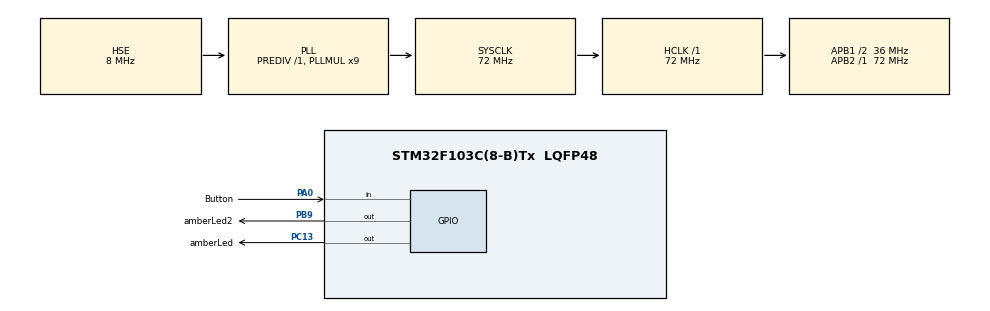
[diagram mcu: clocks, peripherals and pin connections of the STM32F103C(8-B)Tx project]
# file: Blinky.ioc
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Mcu.Family=STM32F1
Mcu.Name=STM32F103C(8-B)Tx
Mcu.Package=LQFP48
Mcu.UserConstants=TIMER1_COUNTER,100000
NVIC.PriorityGroup=NVIC_PRIORITYGROUP_4
NVIC.TIM1_UP_IRQn=true\:0\:0\:false\:false\:true
PA0-WKUP.GPIO_Label=Button
PA0-WKUP.GPIO_PuPd=GPIO_PULLUP
PA0-WKUP.Signal=GPIO_Input
PA13.Mode=Serial_Wire
PA13.Signal=SYS_JTMS-SWDIO
PA14.Mode=Serial_Wire
PA14.Signal=SYS_JTCK-SWCLK
PB9.GPIO_Label=amberLed2
PB9.PinState=GPIO_PIN_SET
PB9.Signal=GPIO_Output
PC13-TAMPER-RTC.GPIO_Label=amberLed
PC13-TAMPER-RTC.PinState=GPIO_PIN_SET
PC13-TAMPER-RTC.Signal=GPIO_Output
PD0-OSC_IN.Mode=HSE-External-Oscillator
PD0-OSC_IN.Signal=RCC_OSC_IN
PD1-OSC_OUT.Mode=HSE-External-Oscillator
PD1-OSC_OUT.Signal=RCC_OSC_OUT
ProjectManager.HeapSize=0x200
ProjectManager.StackSize=0x400
ProjectManager.TargetToolchain=SW4STM32
RCC.AHBFreq_Value=72000000
RCC.APB1CLKDivider=RCC_HCLK_DIV2
RCC.APB1Freq_Value=36000000
RCC.APB1TimFreq_Value=72000000
RCC.APB2Freq_Value=72000000
RCC.APB2TimFreq_Value=72000000
RCC.HCLKFreq_Value=72000000
RCC.PLLMUL=RCC_PLL_MUL9
RCC.PLLSourceVirtual=RCC_PLLSOURCE_HSE
RCC.SYSCLKFreq_VALUE=72000000
RCC.SYSCLKSource=RCC_SYSCLKSOURCE_PLLCLK
RCC.USBFreq_Value=72000000
TIM1.CounterMode=TIM_COUNTERMODE_UP
TIM1.Period=TIMER1_COUNTER
TIM1.TIM_MasterOutputTrigger=TIM_TRGO_UPDATE
VP_TIM1_VS_ClockSourceINT.Mode=Internal
board=Blinky

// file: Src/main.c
/**
  ******************************************************************************
  * File Name          : main.c
  * Description        : Main program body
  ******************************************************************************
  ** This notice applies to any and all portions of this file
  * that are not between comment pairs USER CODE BEGIN and
  * USER CODE END. Other portions of this file, whether
  * inserted by the user or by software development tools
  * are owned by their respective copyright owners.
  *
  * COPYRIGHT(c) 2017 STMicroelectronics
  *
  * Redistribution and use in source and binary forms, with or without modification,
  * are permitted provided that the following conditions are met:
  *   1. Redistributions of source code must retain the above copyright notice,
  *      this list of conditions and the following disclaimer.
  *   2. Redistributions in binary form must reproduce the above copyright notice,
  *      this list of conditions and the following disclaimer in the documentation
  *      and/or other materials provided with the distribution.
  *   3. Neither the name of STMicroelectronics nor the names of its contributors
  *      may be used to endorse or promote products derived from this software
  *      without specific prior written permission.
  *
  * THIS SOFTWARE IS PROVIDED BY THE COPYRIGHT HOLDERS AND CONTRIBUTORS "AS IS"
  * AND ANY EXPRESS OR IMPLIED WARRANTIES, INCLUDING, BUT NOT LIMITED TO, THE
  * IMPLIED WARRANTIES OF MERCHANTABILITY AND FITNESS FOR A PARTICULAR PURPOSE ARE
  * DISCLAIMED. IN NO EVENT SHALL THE COPYRIGHT HOLDER OR CONTRIBUTORS BE LIABLE
  * FOR ANY DIRECT, INDIRECT, INCIDENTAL, SPECIAL, EXEMPLARY, OR CONSEQUENTIAL
  * DAMAGES (INCLUDING, BUT NOT LIMITED TO, PROCUREMENT OF SUBSTITUTE GOODS OR
  * SERVICES; LOSS OF USE, DATA, OR PROFITS; OR BUSINESS INTERRUPTION) HOWEVER
  * CAUSED AND ON ANY THEORY OF LIABILITY, WHETHER IN CONTRACT, STRICT LIABILITY,
  * OR TORT (INCLUDING NEGLIGENCE OR OTHERWISE) ARISING IN ANY WAY OUT OF THE USE
  * OF THIS SOFTWARE, EVEN IF ADVISED OF THE POSSIBILITY OF SUCH DAMAGE.
  *
  ******************************************************************************
  */
#include "main.h"
#include "stm32f1xx_hal.h"

/* USER CODE BEGIN Includes */
#include "Task.h"
#include "LinkedList.h"
/* USER CODE END Includes */

TIM_HandleTypeDef htim1;

/* USER CODE BEGIN PV */
/* Private variables ---------------------------------------------------------*/
int mySignal = 8;
//TCB *currTcb;
linkedList *list;
/* USER CODE END PV */

void SystemClock_Config(void);
static void MX_GPIO_Init(void);
static void MX_TIM1_Init(void);

/* USER CODE BEGIN PFP */
/* Private function prototypes -----------------------------------------------*/
/*int add2Integers(int, int);
int add4Integers(int, int, int, int);
int add5Integers(int, int, int, int, int);
int add6Integers(int, int, int, int, int, int);
int assemblyMain(void);*/
int sub2Integers(int v1, int v2);
int sub5Integers(int v1, int v2, int v3, int v4, int v5);
int sub6Integers(int v1, int v2, int v3, int v4, int v5, int v6);
void task1(void);
void task2(void);
/* USER CODE END PFP */

/* USER CODE BEGIN 0 */
enum blink{on, off};
enum led{led1, led2};
uint32_t tickLed1;
uint32_t tickLed2;
/* USER CODE END 0 */

int main(void)
{

  /* USER CODE BEGIN 1 */
  /*enum blink led1State=on;
  enum blink led2State=on;
  enum led LED=led1;*/
  tickLed1 = HAL_GetTick();
  tickLed2 = HAL_GetTick();
  //TCB *tcb;
  listElement *element;
  volatile int j;
  /* USER CODE END 1 */

  /* MCU Configuration----------------------------------------------------------*/

  /* Reset of all peripherals, Initializes the Flash interface and the Systick. */
  HAL_Init();

  /* Configure the system clock */
  SystemClock_Config();

  /* Initialize all configured peripherals */
  MX_GPIO_Init();
  MX_TIM1_Init();

  /* USER CODE BEGIN 2 */
  /*currTcb = initKernel("MainThread");
  tcb = createThread("Thread1", task1, 256);
  currTcb->next = tcb;
  tcb = createThread("Thread2", task2, 512);
  currTcb->next->next = tcb;
  currTcb->next->next->next = currTcb;*/

  list = initLinkedList();
  element = initElement("MainThread", NULL, 0);
  addElementToBack(list, element);
  element = initElement("Thread1", task1, 256);
  addElementToBack(list, element);
  element = initElement("Thread2", task2, 512);
  addElementToBack(list, element);

  //assemblyMain();
  __HAL_TIM_ENABLE(&htim1);
  HAL_TIM_Base_Start_IT(&htim1);
  /*volatile int val = add2Integers(23, 56);
  volatile int val2 = add4Integers(21, 5, 10, 26);
  volatile int val3 = add5Integers(1, 2, 3, 4, 5);
  volatile int val4 = add6Integers(2, 3, 4, 5, 8, 6);
  if(SCB->CCR & SCB_CCR_STKALIGN){
	  val = val2;
  }*/

  /* USER CODE END 2 */

  /* Infinite loop */
  while (1)
  {

  /* USER CODE BEGIN 3 */

	  j=1;
	  /*uint32_t tick = 0;
	  HAL_GPIO_TogglePin(amberLed2_GPIO_Port, amberLed2_Pin);

	  tick = osKernelSysTick();
	  while(osKernelSysTick() - tick < 500);*/
	  /*switch(LED){
	  case led1:
		  if((HAL_GetTick()-tickLed1) >= 75){
			  HAL_GPIO_TogglePin(amberLed2_GPIO_Port, amberLed2_Pin);
			  tickLed1=HAL_GetTick();
		  }
		  LED=led2;
		  break;
	  case led2:
		  if((HAL_GetTick()-tickLed2) >= 500){
			  HAL_GPIO_TogglePin(amberLed_GPIO_Port, amberLed_Pin);
			  tickLed2=HAL_GetTick();
		  }
		  LED=led1;
		  break;
	  default:
		  LED=led1;
	  }*/

	  /*HAL_GPIO_TogglePin(amberLed_GPIO_Port, amberLed_Pin);
	  HAL_Delay(500);
	  HAL_GPIO_TogglePin(amberLed2_GPIO_Port, amberLed2_Pin);
	  HAL_Delay(75);*/
  }
  /* USER CODE END 3 */

}

/** System Clock Configuration
*/
void SystemClock_Config(void)
{

  RCC_OscInitTypeDef RCC_OscInitStruct;
  RCC_ClkInitTypeDef RCC_ClkInitStruct;

    /**Initializes the CPU, AHB and APB busses clocks
    */
  RCC_OscInitStruct.OscillatorType = RCC_OSCILLATORTYPE_HSE;
  RCC_OscInitStruct.HSEState = RCC_HSE_ON;
  RCC_OscInitStruct.HSEPredivValue = RCC_HSE_PREDIV_DIV1;
  RCC_OscInitStruct.HSIState = RCC_HSI_ON;
  RCC_OscInitStruct.PLL.PLLState = RCC_PLL_ON;
  RCC_OscInitStruct.PLL.PLLSource = RCC_PLLSOURCE_HSE;
  RCC_OscInitStruct.PLL.PLLMUL = RCC_PLL_MUL9;
  if (HAL_RCC_OscConfig(&RCC_OscInitStruct) != HAL_OK)
  {
    _Error_Handler(__FILE__, __LINE__);
  }

    /**Initializes the CPU, AHB and APB busses clocks
    */
  RCC_ClkInitStruct.ClockType = RCC_CLOCKTYPE_HCLK|RCC_CLOCKTYPE_SYSCLK
                              |RCC_CLOCKTYPE_PCLK1|RCC_CLOCKTYPE_PCLK2;
  RCC_ClkInitStruct.SYSCLKSource = RCC_SYSCLKSOURCE_PLLCLK;
  RCC_ClkInitStruct.AHBCLKDivider = RCC_SYSCLK_DIV1;
  RCC_ClkInitStruct.APB1CLKDivider = RCC_HCLK_DIV2;
  RCC_ClkInitStruct.APB2CLKDivider = RCC_HCLK_DIV1;

  if (HAL_RCC_ClockConfig(&RCC_ClkInitStruct, FLASH_LATENCY_2) != HAL_OK)
  {
    _Error_Handler(__FILE__, __LINE__);
  }

    /**Configure the Systick interrupt time
    */
  HAL_SYSTICK_Config(HAL_RCC_GetHCLKFreq()/1000);

    /**Configure the Systick
    */
  HAL_SYSTICK_CLKSourceConfig(SYSTICK_CLKSOURCE_HCLK);

  /* SysTick_IRQn interrupt configuration */
  HAL_NVIC_SetPriority(SysTick_IRQn, 0, 0);
}

/* TIM1 init function */
static void MX_TIM1_Init(void)
{

  TIM_ClockConfigTypeDef sClockSourceConfig;
  TIM_MasterConfigTypeDef sMasterConfig;

  htim1.Instance = TIM1;
  htim1.Init.Prescaler = 0;
  htim1.Init.CounterMode = TIM_COUNTERMODE_UP;
  htim1.Init.Period = TIMER1_COUNTER;
  htim1.Init.ClockDivision = TIM_CLOCKDIVISION_DIV1;
  htim1.Init.RepetitionCounter = 0;
  if (HAL_TIM_Base_Init(&htim1) != HAL_OK)
  {
    _Error_Handler(__FILE__, __LINE__);
  }

  sClockSourceConfig.ClockSource = TIM_CLOCKSOURCE_INTERNAL;
  if (HAL_TIM_ConfigClockSource(&htim1, &sClockSourceConfig) != HAL_OK)
  {
    _Error_Handler(__FILE__, __LINE__);
  }

  sMasterConfig.MasterOutputTrigger = TIM_TRGO_UPDATE;
  sMasterConfig.MasterSlaveMode = TIM_MASTERSLAVEMODE_DISABLE;
  if (HAL_TIMEx_MasterConfigSynchronization(&htim1, &sMasterConfig) != HAL_OK)
  {
    _Error_Handler(__FILE__, __LINE__);
  }

}

/** Configure pins as
        * Analog
        * Input
        * Output
        * EVENT_OUT
        * EXTI
*/
static void MX_GPIO_Init(void)
{

  GPIO_InitTypeDef GPIO_InitStruct;

  /* GPIO Ports Clock Enable */
  __HAL_RCC_GPIOC_CLK_ENABLE();
  __HAL_RCC_GPIOD_CLK_ENABLE();
  __HAL_RCC_GPIOA_CLK_ENABLE();
  __HAL_RCC_GPIOB_CLK_ENABLE();

  /*Configure GPIO pin Output Level */
  HAL_GPIO_WritePin(amberLed_GPIO_Port, amberLed_Pin, GPIO_PIN_SET);

  /*Configure GPIO pin Output Level */
  HAL_GPIO_WritePin(amberLed2_GPIO_Port, amberLed2_Pin, GPIO_PIN_SET);

  /*Configure GPIO pin : amberLed_Pin */
  GPIO_InitStruct.Pin = amberLed_Pin;
  GPIO_InitStruct.Mode = GPIO_MODE_OUTPUT_PP;
  GPIO_InitStruct.Speed = GPIO_SPEED_FREQ_LOW;
  HAL_GPIO_Init(amberLed_GPIO_Port, &GPIO_InitStruct);

  /*Configure GPIO pin : Button_Pin */
  GPIO_InitStruct.Pin = Button_Pin;
  GPIO_InitStruct.Mode = GPIO_MODE_INPUT;
  GPIO_InitStruct.Pull = GPIO_PULLUP;
  HAL_GPIO_Init(Button_GPIO_Port, &GPIO_InitStruct);

  /*Configure GPIO pin : amberLed2_Pin */
  GPIO_InitStruct.Pin = amberLed2_Pin;
  GPIO_InitStruct.Mode = GPIO_MODE_OUTPUT_PP;
  GPIO_InitStruct.Speed = GPIO_SPEED_FREQ_LOW;
  HAL_GPIO_Init(amberLed2_GPIO_Port, &GPIO_InitStruct);

}

/* USER CODE BEGIN 4 */
void task1(void){
	volatile int i=0;

	while(1){
		i+=2;
	}
}

void task2(void){
	volatile int k=0;

	while(1){
		k-=10;
	}
}

int sub2Integers(int v1, int v2){
	return v1-v2;
}

int sub5Integers(int v1, int v2, int v3, int v4, int v5){
	return v1-v2-v3-v4-v5;
}

int sub6Integers(int v1, int v2, int v3, int v4, int v5, int v6){
	return v1-v2-v3-v4-v5-v6;
}
/* USER CODE END 4 */

void _Error_Handler(char * file, int line)
{
  while(1)
  {
  }
}

/************************ (C) COPYRIGHT STMicroelectronics *****END OF FILE****/
